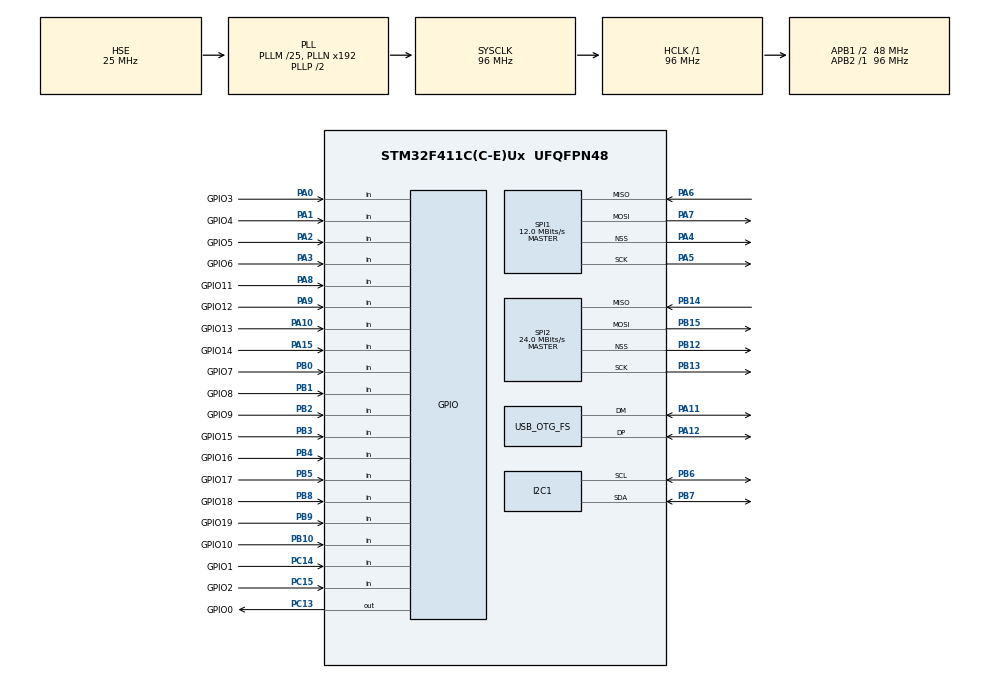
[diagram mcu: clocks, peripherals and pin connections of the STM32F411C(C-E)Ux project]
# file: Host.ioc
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I2C1.I2C_Mode=I2C_Fast
Mcu.Family=STM32F4
Mcu.Name=STM32F411C(C-E)Ux
Mcu.Package=UFQFPN48
NVIC.OTG_FS_IRQn=true\:0\:0\:false\:false\:true\:false\:true
NVIC.PriorityGroup=NVIC_PRIORITYGROUP_4
PA0-WKUP.GPIO_Label=GPIO3
PA0-WKUP.GPIO_PuPd=GPIO_PULLUP
PA0-WKUP.Signal=GPIO_Input
PA1.GPIO_Label=GPIO4
PA1.Signal=GPIO_Input
PA10.GPIO_Label=GPIO13
PA10.Signal=GPIO_Input
PA11.Mode=Device_Only
PA11.Signal=USB_OTG_FS_DM
PA12.Mode=Device_Only
PA12.Signal=USB_OTG_FS_DP
PA13.Mode=Serial_Wire
PA13.Signal=SYS_JTMS-SWDIO
PA14.Mode=Serial_Wire
PA14.Signal=SYS_JTCK-SWCLK
PA15.GPIO_Label=GPIO14
PA15.Signal=GPIO_Input
PA2.GPIO_Label=GPIO5
PA2.Signal=GPIO_Input
PA3.GPIO_Label=GPIO6
PA3.Signal=GPIO_Input
PA4.Mode=NSS_Signal_Hard_Output
PA4.Signal=SPI1_NSS
PA5.Mode=Full_Duplex_Master
PA5.Signal=SPI1_SCK
PA6.Mode=Full_Duplex_Master
PA6.Signal=SPI1_MISO
PA7.Mode=Full_Duplex_Master
PA7.Signal=SPI1_MOSI
PA8.GPIO_Label=GPIO11
PA8.Signal=GPIO_Input
PA9.GPIO_Label=GPIO12
PA9.Signal=GPIO_Input
PB0.GPIO_Label=GPIO7
PB0.Signal=GPIO_Input
PB1.GPIO_Label=GPIO8
PB1.Signal=GPIO_Input
PB10.GPIO_Label=GPIO10
PB10.Signal=GPIO_Input
PB12.Mode=NSS_Signal_Hard_Output
PB12.Signal=SPI2_NSS
PB13.Mode=Full_Duplex_Master
PB13.Signal=SPI2_SCK
PB14.Mode=Full_Duplex_Master
PB14.Signal=SPI2_MISO
PB15.Mode=Full_Duplex_Master
PB15.Signal=SPI2_MOSI
PB2.GPIO_Label=GPIO9
PB2.Signal=GPIO_Input
PB3.GPIO_Label=GPIO15
PB3.Signal=GPIO_Input
PB4.GPIO_Label=GPIO16
PB4.Signal=GPIO_Input
PB5.GPIO_Label=GPIO17
PB5.Signal=GPIO_Input
PB6.Mode=I2C
PB6.Signal=I2C1_SCL
PB7.Mode=I2C
PB7.Signal=I2C1_SDA
PB8.GPIO_Label=GPIO18
PB8.Signal=GPIO_Input
PB9.GPIO_Label=GPIO19
PB9.Signal=GPIO_Input
PC13-ANTI_TAMP.GPIO_Label=GPIO0
PC13-ANTI_TAMP.Signal=GPIO_Output
PC14-OSC32_IN.GPIO_Label=GPIO1
PC14-OSC32_IN.Signal=GPIO_Input
PC15-OSC32_OUT.GPIO_Label=GPIO2
PC15-OSC32_OUT.Signal=GPIO_Input
PH0\ -\ OSC_IN.Mode=HSE-External-Oscillator
PH0\ -\ OSC_IN.Signal=RCC_OSC_IN
PH1\ -\ OSC_OUT.Mode=HSE-External-Oscillator
PH1\ -\ OSC_OUT.Signal=RCC_OSC_OUT
ProjectManager.HeapSize=0x200
ProjectManager.StackSize=0x400
ProjectManager.TargetToolchain=STM32CubeIDE
RCC.48MHZClocksFreq_Value=48000000
RCC.AHBFreq_Value=96000000
RCC.APB1CLKDivider=RCC_HCLK_DIV2
RCC.APB1Freq_Value=48000000
RCC.APB1TimFreq_Value=96000000
RCC.APB2Freq_Value=96000000
RCC.APB2TimFreq_Value=96000000
RCC.CortexFreq_Value=96000000
RCC.HCLKFreq_Value=96000000
RCC.HSE_VALUE=25000000
RCC.HSI_VALUE=16000000
RCC.LSE_VALUE=32768
RCC.PLLM=25
RCC.SYSCLKFreq_VALUE=96000000
RCC.SYSCLKSource=RCC_SYSCLKSOURCE_PLLCLK
RCC.VCOOutputFreq_Value=192000000
SPI1.BaudRatePrescaler=SPI_BAUDRATEPRESCALER_8
SPI1.CalculateBaudRate=12.0 MBits/s
SPI1.Direction=SPI_DIRECTION_2LINES
SPI1.Mode=SPI_MODE_MASTER
SPI1.VirtualNSS=VM_NSSHARD
SPI1.VirtualType=VM_MASTER
SPI2.CalculateBaudRate=24.0 MBits/s
SPI2.Direction=SPI_DIRECTION_2LINES
SPI2.Mode=SPI_MODE_MASTER
SPI2.VirtualNSS=VM_NSSHARD
SPI2.VirtualType=VM_MASTER
USB_DEVICE.CLASS_NAME_FS=CDC
USB_DEVICE.VirtualMode=Cdc
USB_DEVICE.VirtualModeFS=Cdc_FS
USB_OTG_FS.VirtualMode=Device_Only
VP_USB_DEVICE_VS_USB_DEVICE_CDC_FS.Mode=CDC_FS
board=custom

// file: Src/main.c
/* USER CODE BEGIN Header */
/**
  ******************************************************************************
  * @file           : main.c
  * @brief          : Main program body
  ******************************************************************************
  * @attention
  *
  * <h2><center>&copy; Copyright (c) 2021 STMicroelectronics.
  * All rights reserved.</center></h2>
  *
  * This software component is licensed by ST under BSD 3-Clause license,
  * the "License"; You may not use this file except in compliance with the
  * License. You may obtain a copy of the License at:
  *                        opensource.org/licenses/BSD-3-Clause
  *
  ******************************************************************************
  */
/* USER CODE END Header */
#include "main.h"
#include "usb_device.h"

I2C_HandleTypeDef hi2c1;

SPI_HandleTypeDef hspi1;
SPI_HandleTypeDef hspi2;

void SystemClock_Config(void);
static void MX_GPIO_Init(void);
static void MX_I2C1_Init(void);
static void MX_SPI1_Init(void);
static void MX_SPI2_Init(void);

int main(void)
{

  /* MCU Configuration--------------------------------------------------------*/

  /* Reset of all peripherals, Initializes the Flash interface and the Systick. */
  HAL_Init();

  /* Configure the system clock */
  SystemClock_Config();

  /* Initialize all configured peripherals */
  MX_GPIO_Init();
  MX_I2C1_Init();
  MX_SPI1_Init();
  MX_SPI2_Init();
  MX_USB_DEVICE_Init();
  /* USER CODE BEGIN 2 */
  printf("hello RemoteIIC\r\n");
  /* USER CODE END 2 */

  /* Infinite loop */
  while (1)
  {

  }
}

void SystemClock_Config(void)
{
  RCC_OscInitTypeDef RCC_OscInitStruct = {0};
  RCC_ClkInitTypeDef RCC_ClkInitStruct = {0};

  /** Configure the main internal regulator output voltage
  */
  __HAL_RCC_PWR_CLK_ENABLE();
  __HAL_PWR_VOLTAGESCALING_CONFIG(PWR_REGULATOR_VOLTAGE_SCALE1);
  /** Initializes the RCC Oscillators according to the specified parameters
  * in the RCC_OscInitTypeDef structure.
  */
  RCC_OscInitStruct.OscillatorType = RCC_OSCILLATORTYPE_HSE;
  RCC_OscInitStruct.HSEState = RCC_HSE_ON;
  RCC_OscInitStruct.PLL.PLLState = RCC_PLL_ON;
  RCC_OscInitStruct.PLL.PLLSource = RCC_PLLSOURCE_HSE;
  RCC_OscInitStruct.PLL.PLLM = 25;
  RCC_OscInitStruct.PLL.PLLN = 192;
  RCC_OscInitStruct.PLL.PLLP = RCC_PLLP_DIV2;
  RCC_OscInitStruct.PLL.PLLQ = 4;
  if (HAL_RCC_OscConfig(&RCC_OscInitStruct) != HAL_OK)
  {
    Error_Handler();
  }
  /** Initializes the CPU, AHB and APB buses clocks
  */
  RCC_ClkInitStruct.ClockType = RCC_CLOCKTYPE_HCLK|RCC_CLOCKTYPE_SYSCLK
                              |RCC_CLOCKTYPE_PCLK1|RCC_CLOCKTYPE_PCLK2;
  RCC_ClkInitStruct.SYSCLKSource = RCC_SYSCLKSOURCE_PLLCLK;
  RCC_ClkInitStruct.AHBCLKDivider = RCC_SYSCLK_DIV1;
  RCC_ClkInitStruct.APB1CLKDivider = RCC_HCLK_DIV2;
  RCC_ClkInitStruct.APB2CLKDivider = RCC_HCLK_DIV1;

  if (HAL_RCC_ClockConfig(&RCC_ClkInitStruct, FLASH_LATENCY_3) != HAL_OK)
  {
    Error_Handler();
  }
}

static void MX_I2C1_Init(void)
{

  hi2c1.Instance = I2C1;
  hi2c1.Init.ClockSpeed = 400000;
  hi2c1.Init.DutyCycle = I2C_DUTYCYCLE_2;
  hi2c1.Init.OwnAddress1 = 0;
  hi2c1.Init.AddressingMode = I2C_ADDRESSINGMODE_7BIT;
  hi2c1.Init.DualAddressMode = I2C_DUALADDRESS_DISABLE;
  hi2c1.Init.OwnAddress2 = 0;
  hi2c1.Init.GeneralCallMode = I2C_GENERALCALL_DISABLE;
  hi2c1.Init.NoStretchMode = I2C_NOSTRETCH_DISABLE;
  if (HAL_I2C_Init(&hi2c1) != HAL_OK)
  {
    Error_Handler();
  }

}

static void MX_SPI1_Init(void)
{

  /* SPI1 parameter configuration*/
  hspi1.Instance = SPI1;
  hspi1.Init.Mode = SPI_MODE_MASTER;
  hspi1.Init.Direction = SPI_DIRECTION_2LINES;
  hspi1.Init.DataSize = SPI_DATASIZE_8BIT;
  hspi1.Init.CLKPolarity = SPI_POLARITY_LOW;
  hspi1.Init.CLKPhase = SPI_PHASE_1EDGE;
  hspi1.Init.NSS = SPI_NSS_HARD_OUTPUT;
  hspi1.Init.BaudRatePrescaler = SPI_BAUDRATEPRESCALER_8;
  hspi1.Init.FirstBit = SPI_FIRSTBIT_MSB;
  hspi1.Init.TIMode = SPI_TIMODE_DISABLE;
  hspi1.Init.CRCCalculation = SPI_CRCCALCULATION_DISABLE;
  hspi1.Init.CRCPolynomial = 10;
  if (HAL_SPI_Init(&hspi1) != HAL_OK)
  {
    Error_Handler();
  }

}

static void MX_SPI2_Init(void)
{

  /* SPI2 parameter configuration*/
  hspi2.Instance = SPI2;
  hspi2.Init.Mode = SPI_MODE_MASTER;
  hspi2.Init.Direction = SPI_DIRECTION_2LINES;
  hspi2.Init.DataSize = SPI_DATASIZE_8BIT;
  hspi2.Init.CLKPolarity = SPI_POLARITY_LOW;
  hspi2.Init.CLKPhase = SPI_PHASE_1EDGE;
  hspi2.Init.NSS = SPI_NSS_HARD_OUTPUT;
  hspi2.Init.BaudRatePrescaler = SPI_BAUDRATEPRESCALER_2;
  hspi2.Init.FirstBit = SPI_FIRSTBIT_MSB;
  hspi2.Init.TIMode = SPI_TIMODE_DISABLE;
  hspi2.Init.CRCCalculation = SPI_CRCCALCULATION_DISABLE;
  hspi2.Init.CRCPolynomial = 10;
  if (HAL_SPI_Init(&hspi2) != HAL_OK)
  {
    Error_Handler();
  }

}

static void MX_GPIO_Init(void)
{
  GPIO_InitTypeDef GPIO_InitStruct = {0};

  /* GPIO Ports Clock Enable */
  __HAL_RCC_GPIOC_CLK_ENABLE();
  __HAL_RCC_GPIOH_CLK_ENABLE();
  __HAL_RCC_GPIOA_CLK_ENABLE();
  __HAL_RCC_GPIOB_CLK_ENABLE();

  /*Configure GPIO pin Output Level */
  HAL_GPIO_WritePin(GPIO0_GPIO_Port, GPIO0_Pin, GPIO_PIN_RESET);

  /*Configure GPIO pin : GPIO0_Pin */
  GPIO_InitStruct.Pin = GPIO0_Pin;
  GPIO_InitStruct.Mode = GPIO_MODE_OUTPUT_PP;
  GPIO_InitStruct.Pull = GPIO_NOPULL;
  GPIO_InitStruct.Speed = GPIO_SPEED_FREQ_LOW;
  HAL_GPIO_Init(GPIO0_GPIO_Port, &GPIO_InitStruct);

  /*Configure GPIO pins : GPIO1_Pin GPIO2_Pin */
  GPIO_InitStruct.Pin = GPIO1_Pin|GPIO2_Pin;
  GPIO_InitStruct.Mode = GPIO_MODE_INPUT;
  GPIO_InitStruct.Pull = GPIO_NOPULL;
  HAL_GPIO_Init(GPIOC, &GPIO_InitStruct);

  /*Configure GPIO pin : GPIO3_Pin */
  GPIO_InitStruct.Pin = GPIO3_Pin;
  GPIO_InitStruct.Mode = GPIO_MODE_INPUT;
  GPIO_InitStruct.Pull = GPIO_PULLUP;
  HAL_GPIO_Init(GPIO3_GPIO_Port, &GPIO_InitStruct);

  /*Configure GPIO pins : GPIO4_Pin GPIO5_Pin GPIO6_Pin GPIO11_Pin
                           GPIO12_Pin GPIO13_Pin GPIO14_Pin */
  GPIO_InitStruct.Pin = GPIO4_Pin|GPIO5_Pin|GPIO6_Pin|GPIO11_Pin
                          |GPIO12_Pin|GPIO13_Pin|GPIO14_Pin;
  GPIO_InitStruct.Mode = GPIO_MODE_INPUT;
  GPIO_InitStruct.Pull = GPIO_NOPULL;
  HAL_GPIO_Init(GPIOA, &GPIO_InitStruct);

  /*Configure GPIO pins : GPIO7_Pin GPIO8_Pin GPIO9_Pin GPIO10_Pin
                           GPIO15_Pin GPIO16_Pin GPIO17_Pin GPIO18_Pin
                           GPIO19_Pin */
  GPIO_InitStruct.Pin = GPIO7_Pin|GPIO8_Pin|GPIO9_Pin|GPIO10_Pin
                          |GPIO15_Pin|GPIO16_Pin|GPIO17_Pin|GPIO18_Pin
                          |GPIO19_Pin;
  GPIO_InitStruct.Mode = GPIO_MODE_INPUT;
  GPIO_InitStruct.Pull = GPIO_NOPULL;
  HAL_GPIO_Init(GPIOB, &GPIO_InitStruct);

}

void Error_Handler(void)
{
  __disable_irq();
  while (1)
  {
  }
}

/************************ (C) COPYRIGHT STMicroelectronics *****END OF FILE****/
